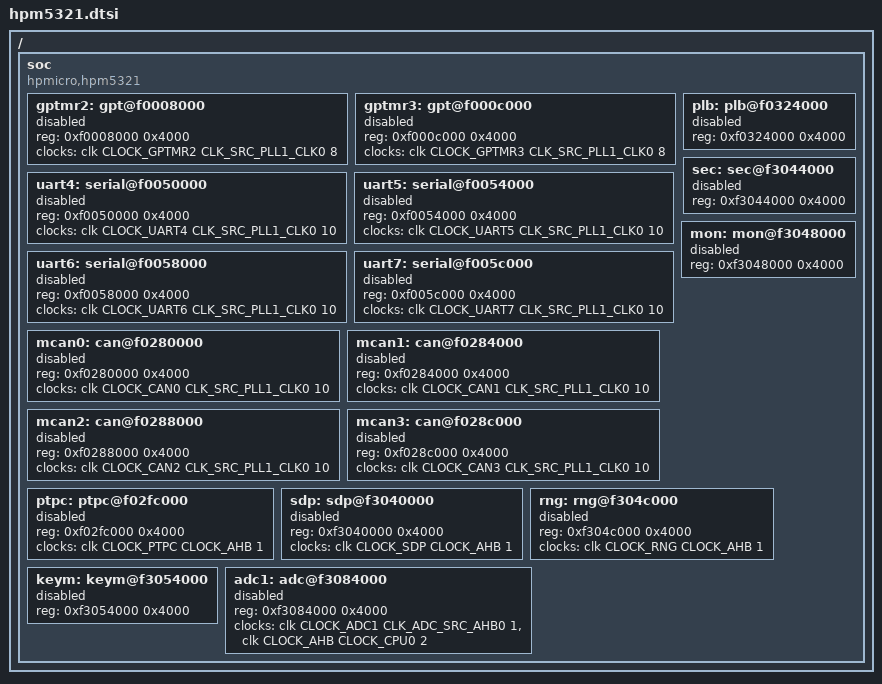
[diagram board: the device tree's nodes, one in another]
/*
* Copyright (c) 2026 HPMicro
* SPDX-License-Identifier: Apache-2.0
*/

#include <dt-bindings/clock/hpm5361-clocks.h>
#include <hpmicro/HPM5300/hpm53xx.dtsi>

/ {
	soc {
		compatible = "hpmicro,hpm5321", "hpmicro,hpm53xx";
		gptmr2: gpt@f0008000 {
			reg = <0xf0008000 0x4000>;
			clocks = <&clk CLOCK_GPTMR2 CLK_SRC_PLL1_CLK0 8>;
			status = "disabled";
		};

		gptmr3: gpt@f000c000 {
			reg = <0xf000c000 0x4000>;
			clocks = <&clk CLOCK_GPTMR3 CLK_SRC_PLL1_CLK0 8>;
			status = "disabled";
		};

		uart4: serial@f0050000 {
			reg = <0xf0050000 0x4000>;
			clocks = <&clk CLOCK_UART4 CLK_SRC_PLL1_CLK0 10>;
			status = "disabled";
		};

		uart5: serial@f0054000 {
			reg = <0xf0054000 0x4000>;
			clocks = <&clk CLOCK_UART5 CLK_SRC_PLL1_CLK0 10>;
			status = "disabled";
		};

		uart6: serial@f0058000 {
			reg = <0xf0058000 0x4000>;
			clocks = <&clk CLOCK_UART6 CLK_SRC_PLL1_CLK0 10>;
			status = "disabled";
		};

		uart7: serial@f005c000 {
			reg = <0xf005c000 0x4000>;
			clocks = <&clk CLOCK_UART7 CLK_SRC_PLL1_CLK0 10>;
			status = "disabled";
		};

		mcan0: can@f0280000 {
			reg = <0xf0280000 0x4000>;
			clocks = <&clk CLOCK_CAN0 CLK_SRC_PLL1_CLK0 10>;
			status = "disabled";
		};

		mcan1: can@f0284000 {
			reg = <0xf0284000 0x4000>;
			clocks = <&clk CLOCK_CAN1 CLK_SRC_PLL1_CLK0 10>;
			status = "disabled";
		};

		mcan2: can@f0288000 {
			reg = <0xf0288000 0x4000>;
			clocks = <&clk CLOCK_CAN2 CLK_SRC_PLL1_CLK0 10>;
			status = "disabled";
		};

		mcan3: can@f028c000 {
			reg = <0xf028c000 0x4000>;
			clocks = <&clk CLOCK_CAN3 CLK_SRC_PLL1_CLK0 10>;
			status = "disabled";
		};

		ptpc: ptpc@f02fc000 {
			reg = <0xf02fc000 0x4000>;
			clocks = <&clk CLOCK_PTPC CLOCK_AHB 1>;
			status = "disabled";
		};

		plb: plb@f0324000 {
			reg = <0xf0324000 0x4000>;
			status = "disabled";
		};

		sdp: sdp@f3040000 {
			reg = <0xf3040000 0x4000>;
			clocks = <&clk CLOCK_SDP CLOCK_AHB 1>;
			status = "disabled";
		};

		sec: sec@f3044000 {
			reg = <0xf3044000 0x4000>;
			status = "disabled";
		};

		mon: mon@f3048000 {
			reg = <0xf3048000 0x4000>;
			status = "disabled";
		};

		rng: rng@f304c000 {
			reg = <0xf304c000 0x4000>;
			clocks = <&clk CLOCK_RNG CLOCK_AHB 1>;
			status = "disabled";
		};

		keym: keym@f3054000 {
			reg = <0xf3054000 0x4000>;
			status = "disabled";
		};

		adc1: adc@f3084000 {
			reg = <0xf3084000 0x4000>;
			clocks = <&clk CLOCK_ADC1 CLK_ADC_SRC_AHB0 1>,
				<&clk CLOCK_AHB CLOCK_CPU0 2>;
			status = "disabled";
		};
	};
};
